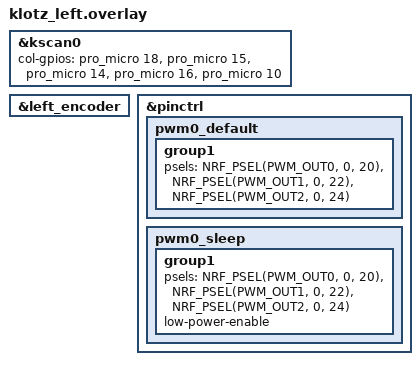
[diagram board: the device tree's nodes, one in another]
/*
 * Copyright (c) 2022 GEIST
 *
 * SPDX-License-Identifier: MIT
 */

#include "klotz.dtsi"

&kscan0 {
	col-gpios
		= <&pro_micro 18 GPIO_ACTIVE_HIGH>
		, <&pro_micro 15 GPIO_ACTIVE_HIGH>
		, <&pro_micro 14 GPIO_ACTIVE_HIGH>
		, <&pro_micro 16 GPIO_ACTIVE_HIGH>
		, <&pro_micro 10 GPIO_ACTIVE_HIGH>
		;
};

&left_encoder {
	status = "okay";
};

&pinctrl {
    // Other Pinctrl definitions go here
    pwm0_default: pwm0_default {
        group1 {
            psels = <NRF_PSEL(PWM_OUT0, 0, 20)>, // LED 0
                    <NRF_PSEL(PWM_OUT1, 0, 22)>, // LED 1
                    <NRF_PSEL(PWM_OUT2, 0, 24)>; // LED 2
        };
    };
    pwm0_sleep: pwm0_sleep {
        group1 {
            psels = <NRF_PSEL(PWM_OUT0, 0, 20)>, // LED 0
                    <NRF_PSEL(PWM_OUT1, 0, 22)>, // LED 1
                    <NRF_PSEL(PWM_OUT2, 0, 24)>; // LED 2
            low-power-enable;
        };
    };
};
